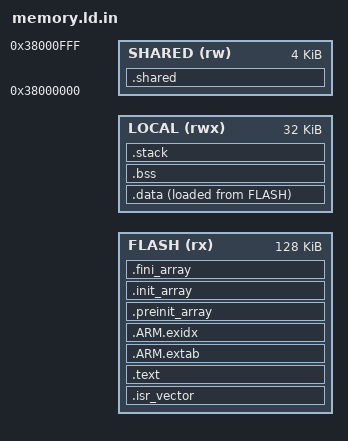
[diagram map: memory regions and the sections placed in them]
/* Explicit tiny link reservation; no PCB, boot-option or execution claim. */
ENTRY(Reset_Handler)
MEMORY {
  FLASH (rx) : ORIGIN = @reference_flash@, LENGTH = 128K
  LOCAL (rwx) : ORIGIN = @reference_ram@, LENGTH = 32K
  SHARED (rw) : ORIGIN = 0x38000000, LENGTH = 4K
}
_estack = ORIGIN(LOCAL) + LENGTH(LOCAL);
SECTIONS {
  .isr_vector : { KEEP(*(.isr_vector)) } > FLASH
  .text : { *(.text*) *(.rodata*) KEEP(*(.init)) KEEP(*(.fini)) } > FLASH
  .ARM.extab : { *(.ARM.extab*) } > FLASH
  .ARM.exidx : {
    __exidx_start = .; *(.ARM.exidx*) __exidx_end = .;
  } > FLASH
  .preinit_array : {
    PROVIDE_HIDDEN(__preinit_array_start = .);
    KEEP(*(.preinit_array*))
    PROVIDE_HIDDEN(__preinit_array_end = .);
  } > FLASH
  .init_array : {
    PROVIDE_HIDDEN(__init_array_start = .);
    KEEP(*(SORT(.init_array.*))) KEEP(*(.init_array))
    PROVIDE_HIDDEN(__init_array_end = .);
  } > FLASH
  .fini_array : {
    PROVIDE_HIDDEN(__fini_array_start = .);
    KEEP(*(SORT(.fini_array.*))) KEEP(*(.fini_array))
    PROVIDE_HIDDEN(__fini_array_end = .);
  } > FLASH
  _sidata = LOADADDR(.data);
  .data : { . = ALIGN(8); _sdata = .; *(.data*) . = ALIGN(8); _edata = .; }
    > LOCAL AT > FLASH
  .bss (NOLOAD) : {
    . = ALIGN(8); _sbss = .; *(.bss*) *(COMMON) . = ALIGN(8); _ebss = .;
  } > LOCAL
  .shared (NOLOAD) : {
    __shared_begin = .; . += LENGTH(SHARED); __shared_end = .;
  } > SHARED
  .stack (NOLOAD) : { . = ALIGN(8); . += 2048; } > LOCAL
  PROVIDE(end = _ebss);
  ASSERT(_ebss + 2048 <= _estack, "Local data overlaps reference stack")
  ASSERT(SIZEOF(.shared) == 4096, "Exact shared reservation changed")
}
